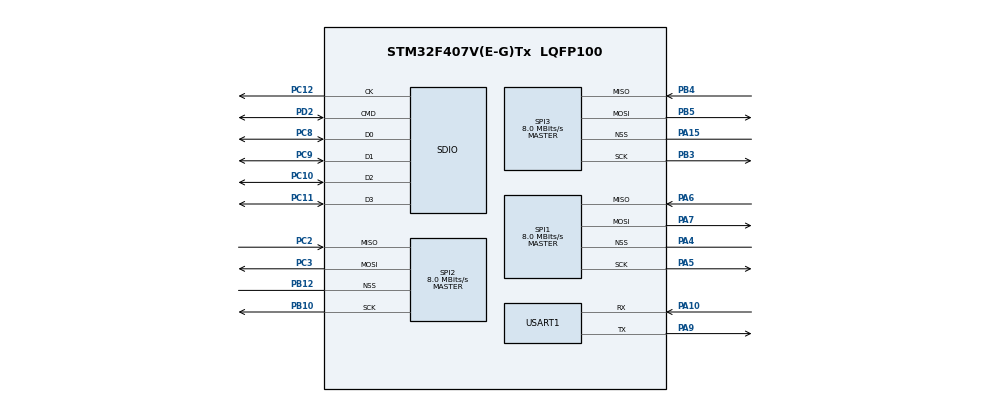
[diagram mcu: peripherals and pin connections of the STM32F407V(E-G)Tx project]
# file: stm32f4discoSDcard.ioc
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Mcu.Family=STM32F4
Mcu.Name=STM32F407V(E-G)Tx
Mcu.Package=LQFP100
NVIC.PriorityGroup=NVIC_PRIORITYGROUP_4
PA10.Mode=Asynchronous
PA10.Signal=USART1_RX
PA15.Mode=NSS_Signal_Hard
PA15.Signal=SPI3_NSS
PA4.Mode=NSS_Signal_Hard
PA4.Signal=SPI1_NSS
PA5.Mode=Full_Duplex_Master
PA5.Signal=SPI1_SCK
PA6.Mode=Full_Duplex_Master
PA6.Signal=SPI1_MISO
PA7.Mode=Full_Duplex_Master
PA7.Signal=SPI1_MOSI
PA9.Mode=Asynchronous
PA9.Signal=USART1_TX
PB10.Mode=Full_Duplex_Master
PB10.Signal=SPI2_SCK
PB12.Mode=NSS_Signal_Hard
PB12.Signal=SPI2_NSS
PB3.Mode=Full_Duplex_Master
PB3.Signal=SPI3_SCK
PB4.Mode=Full_Duplex_Master
PB4.Signal=SPI3_MISO
PB5.Mode=Full_Duplex_Master
PB5.Signal=SPI3_MOSI
PC10.Mode=SD_4_bits_Wide_bus
PC10.Signal=SDIO_D2
PC11.Mode=SD_4_bits_Wide_bus
PC11.Signal=SDIO_D3
PC12.Mode=SD_4_bits_Wide_bus
PC12.Signal=SDIO_CK
PC2.Mode=Full_Duplex_Master
PC2.Signal=SPI2_MISO
PC3.Mode=Full_Duplex_Master
PC3.Signal=SPI2_MOSI
PC6.Signal=SDIO_D6
PC8.Mode=SD_4_bits_Wide_bus
PC8.Signal=SDIO_D0
PC9.Mode=SD_4_bits_Wide_bus
PC9.Signal=SDIO_D1
PD2.Mode=SD_4_bits_Wide_bus
PD2.Signal=SDIO_CMD
ProjectManager.TargetToolchain=MDK-ARM V5
RCC.48MHZClocksFreq_Value=48000000
RCC.AHBFreq_Value=16000000
RCC.APB1Freq_Value=16000000
RCC.APB2Freq_Value=16000000
RCC.CortexFreq_Value=16000000
RCC.HSE_VALUE=25000000
RCC.HSI_VALUE=16000000
RCC.LSE_VALUE=32768
RCC.SYSCLKFreq_VALUE=16000000
RCC.VCOOutputFreq_Value=192000000
SDIO.BusWide=SDIO_BUS_WIDE_1B
SDIO.WideMode=SDIO_BUS_WIDE_4B
SPI1.CalculateBaudRate=8.0 MBits/s
SPI1.Mode=SPI_MODE_MASTER
SPI1.VirtualNSS=VM_NSSHARD
SPI2.CalculateBaudRate=8.0 MBits/s
SPI2.Mode=SPI_MODE_MASTER
SPI2.VirtualNSS=VM_NSSHARD
SPI3.CalculateBaudRate=8.0 MBits/s
SPI3.Mode=SPI_MODE_MASTER
SPI3.VirtualNSS=VM_NSSHARD
VP_FATFS_VS_Generic.Mode=User_defined
VP_FATFS_VS_SDIO.Mode=SDIO
board=stm32f4discoSDcard

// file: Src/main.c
/**
  ******************************************************************************
  * File Name          : main.c
  * Description        : Main program body
  ******************************************************************************
  *
  * COPYRIGHT(c) 2015 STMicroelectronics
  *
  * Redistribution and use in source and binary forms, with or without modification,
  * are permitted provided that the following conditions are met:
  *   1. Redistributions of source code must retain the above copyright notice,
  *      this list of conditions and the following disclaimer.
  *   2. Redistributions in binary form must reproduce the above copyright notice,
  *      this list of conditions and the following disclaimer in the documentation
  *      and/or other materials provided with the distribution.
  *   3. Neither the name of STMicroelectronics nor the names of its contributors
  *      may be used to endorse or promote products derived from this software
  *      without specific prior written permission.
  *
  * THIS SOFTWARE IS PROVIDED BY THE COPYRIGHT HOLDERS AND CONTRIBUTORS "AS IS"
  * AND ANY EXPRESS OR IMPLIED WARRANTIES, INCLUDING, BUT NOT LIMITED TO, THE
  * IMPLIED WARRANTIES OF MERCHANTABILITY AND FITNESS FOR A PARTICULAR PURPOSE ARE
  * DISCLAIMED. IN NO EVENT SHALL THE COPYRIGHT HOLDER OR CONTRIBUTORS BE LIABLE
  * FOR ANY DIRECT, INDIRECT, INCIDENTAL, SPECIAL, EXEMPLARY, OR CONSEQUENTIAL
  * DAMAGES (INCLUDING, BUT NOT LIMITED TO, PROCUREMENT OF SUBSTITUTE GOODS OR
  * SERVICES; LOSS OF USE, DATA, OR PROFITS; OR BUSINESS INTERRUPTION) HOWEVER
  * CAUSED AND ON ANY THEORY OF LIABILITY, WHETHER IN CONTRACT, STRICT LIABILITY,
  * OR TORT (INCLUDING NEGLIGENCE OR OTHERWISE) ARISING IN ANY WAY OUT OF THE USE
  * OF THIS SOFTWARE, EVEN IF ADVISED OF THE POSSIBILITY OF SUCH DAMAGE.
  *
  ******************************************************************************
  */
#include "stm32f4xx_hal.h"
#include "fatfs.h"

SD_HandleTypeDef hsd;
HAL_SD_CardInfoTypedef SDCardInfo;

SPI_HandleTypeDef hspi1;
SPI_HandleTypeDef hspi2;
SPI_HandleTypeDef hspi3;

UART_HandleTypeDef huart1;

/* USER CODE BEGIN PV */
/* Private variables ---------------------------------------------------------*/
FRESULT res;
FILINFO fno;
FIL fil;
DIR dir;
FATFS fs32;
const TCHAR rwmode = 0x01;
char* path;
/* USER CODE END PV */

void SystemClock_Config(void);
static void MX_GPIO_Init(void);
static void MX_SDIO_SD_Init(void);
static void MX_SPI1_Init(void);
static void MX_SPI2_Init(void);
static void MX_SPI3_Init(void);
static void MX_USART1_UART_Init(void);

/* USER CODE BEGIN PFP */
/* Private function prototypes -----------------------------------------------*/

/* USER CODE END PFP */

int main(void)
{

  /* MCU Configuration----------------------------------------------------------*/

  /* Reset of all peripherals, Initializes the Flash interface and the Systick. */
  HAL_Init();

  /* Configure the system clock */
  SystemClock_Config();

  /* Initialize all configured peripherals */
  MX_GPIO_Init();
  MX_SDIO_SD_Init();
  MX_SPI1_Init();
  MX_SPI2_Init();
  MX_SPI3_Init();
  MX_USART1_UART_Init();
  MX_FATFS_Init();

  /* USER CODE BEGIN 2 */
	res = f_mount(&fs32,&rwmode,1);

  /* USER CODE END 2 */

  /* Infinite loop */
  while (1)
  {

  }

}

/** System Clock Configuration
*/
void SystemClock_Config(void)
{

  RCC_OscInitTypeDef RCC_OscInitStruct;

  __PWR_CLK_ENABLE();

  __HAL_PWR_VOLTAGESCALING_CONFIG(PWR_REGULATOR_VOLTAGE_SCALE2);

  RCC_OscInitStruct.OscillatorType = RCC_OSCILLATORTYPE_HSI;
  RCC_OscInitStruct.HSIState = RCC_HSI_ON;
  RCC_OscInitStruct.HSICalibrationValue = 16;
  RCC_OscInitStruct.PLL.PLLState = RCC_PLL_ON;
  RCC_OscInitStruct.PLL.PLLSource = RCC_PLLSOURCE_HSI;
  RCC_OscInitStruct.PLL.PLLM = 16;
  RCC_OscInitStruct.PLL.PLLN = 192;
  RCC_OscInitStruct.PLL.PLLP = RCC_PLLP_DIV2;
  RCC_OscInitStruct.PLL.PLLQ = 4;
  HAL_RCC_OscConfig(&RCC_OscInitStruct);

  HAL_SYSTICK_Config(HAL_RCC_GetHCLKFreq()/1000);

  HAL_SYSTICK_CLKSourceConfig(SYSTICK_CLKSOURCE_HCLK);

}

/* SDIO init function */
void MX_SDIO_SD_Init(void)
{

  hsd.Instance = SDIO;
  hsd.Init.ClockEdge = SDIO_CLOCK_EDGE_RISING;
  hsd.Init.ClockBypass = SDIO_CLOCK_BYPASS_DISABLE;
  hsd.Init.ClockPowerSave = SDIO_CLOCK_POWER_SAVE_DISABLE;
  hsd.Init.BusWide = SDIO_BUS_WIDE_1B;
  hsd.Init.HardwareFlowControl = SDIO_HARDWARE_FLOW_CONTROL_DISABLE;
  hsd.Init.ClockDiv = 0;

}

/* SPI1 init function */
void MX_SPI1_Init(void)
{

  hspi1.Instance = SPI1;
  hspi1.Init.Mode = SPI_MODE_MASTER;
  hspi1.Init.Direction = SPI_DIRECTION_2LINES;
  hspi1.Init.DataSize = SPI_DATASIZE_8BIT;
  hspi1.Init.CLKPolarity = SPI_POLARITY_LOW;
  hspi1.Init.CLKPhase = SPI_PHASE_1EDGE;
  hspi1.Init.NSS = SPI_NSS_HARD_OUTPUT;
  hspi1.Init.BaudRatePrescaler = SPI_BAUDRATEPRESCALER_2;
  hspi1.Init.FirstBit = SPI_FIRSTBIT_MSB;
  hspi1.Init.TIMode = SPI_TIMODE_DISABLED;
  hspi1.Init.CRCCalculation = SPI_CRCCALCULATION_DISABLED;
  hspi1.Init.CRCPolynomial = 10;
  HAL_SPI_Init(&hspi1);

}

/* SPI2 init function */
void MX_SPI2_Init(void)
{

  hspi2.Instance = SPI2;
  hspi2.Init.Mode = SPI_MODE_MASTER;
  hspi2.Init.Direction = SPI_DIRECTION_2LINES;
  hspi2.Init.DataSize = SPI_DATASIZE_8BIT;
  hspi2.Init.CLKPolarity = SPI_POLARITY_LOW;
  hspi2.Init.CLKPhase = SPI_PHASE_1EDGE;
  hspi2.Init.NSS = SPI_NSS_HARD_OUTPUT;
  hspi2.Init.BaudRatePrescaler = SPI_BAUDRATEPRESCALER_2;
  hspi2.Init.FirstBit = SPI_FIRSTBIT_MSB;
  hspi2.Init.TIMode = SPI_TIMODE_DISABLED;
  hspi2.Init.CRCCalculation = SPI_CRCCALCULATION_DISABLED;
  hspi2.Init.CRCPolynomial = 10;
  HAL_SPI_Init(&hspi2);

}

/* SPI3 init function */
void MX_SPI3_Init(void)
{

  hspi3.Instance = SPI3;
  hspi3.Init.Mode = SPI_MODE_MASTER;
  hspi3.Init.Direction = SPI_DIRECTION_2LINES;
  hspi3.Init.DataSize = SPI_DATASIZE_8BIT;
  hspi3.Init.CLKPolarity = SPI_POLARITY_LOW;
  hspi3.Init.CLKPhase = SPI_PHASE_1EDGE;
  hspi3.Init.NSS = SPI_NSS_HARD_OUTPUT;
  hspi3.Init.BaudRatePrescaler = SPI_BAUDRATEPRESCALER_2;
  hspi3.Init.FirstBit = SPI_FIRSTBIT_MSB;
  hspi3.Init.TIMode = SPI_TIMODE_DISABLED;
  hspi3.Init.CRCCalculation = SPI_CRCCALCULATION_DISABLED;
  hspi3.Init.CRCPolynomial = 10;
  HAL_SPI_Init(&hspi3);

}

/* USART1 init function */
void MX_USART1_UART_Init(void)
{

  huart1.Instance = USART1;
  huart1.Init.BaudRate = 115200;
  huart1.Init.WordLength = UART_WORDLENGTH_8B;
  huart1.Init.StopBits = UART_STOPBITS_1;
  huart1.Init.Parity = UART_PARITY_NONE;
  huart1.Init.Mode = UART_MODE_TX_RX;
  huart1.Init.HwFlowCtl = UART_HWCONTROL_NONE;
  huart1.Init.OverSampling = UART_OVERSAMPLING_16;
  HAL_UART_Init(&huart1);

}

/** Pinout Configuration
*/
void MX_GPIO_Init(void)
{

  /* GPIO Ports Clock Enable */
  __GPIOC_CLK_ENABLE();
  __GPIOA_CLK_ENABLE();
  __GPIOB_CLK_ENABLE();
  __GPIOD_CLK_ENABLE();

}

/************************ (C) COPYRIGHT STMicroelectronics *****END OF FILE****/
